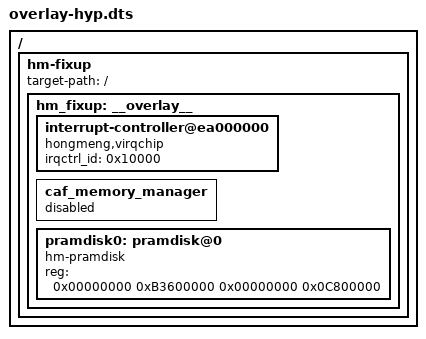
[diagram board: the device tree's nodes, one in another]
/dts-v1/;
/plugin/;

/* override conflict kirin990_chip_cs2 entries */
/ {
	hm-fixup {
		target-path = "/";
		hm_fixup: __overlay__ {};
	};
};

&hm_fixup {
	/* disable GIC to avoid hmkernel probe it */
	interrupt-controller@ea000000 {
		compatible = "hongmeng,virqchip";
		/* the value must be positive */
		irqctrl_id = <0x10000>;
	};

	/* disable mem manger for mali */
	caf_memory_manager {
		status = "disabled";
	};

	/*
	 * pramdisk should be mapped as normal memory in kernel, not IOMEM.
	 * add a node to m536a-hyp.dts. memory range in this node should be
	 * exactly the same as the one in m536a-hyp.dts
	 */
	pramdisk0: pramdisk@0 {
		compatible = "hm-pramdisk", "hm-reserved-memory";
		reg = <0x00000000 0xB3600000 0x00000000 0x0C800000>;
	};
};
